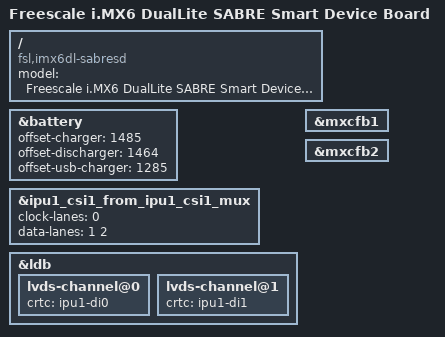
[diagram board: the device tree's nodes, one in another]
// SPDX-License-Identifier: GPL-2.0
//
// Copyright (C) 2013 Freescale Semiconductor, Inc.

/dts-v1/;

#include "imx6dl.dtsi"
#include "imx6qdl-sabresd.dtsi"

/ {
	model = "Freescale i.MX6 DualLite SABRE Smart Device Board";
	compatible = "fsl,imx6dl-sabresd", "fsl,imx6dl";
};

&battery {
	offset-charger = <1485>;
	offset-discharger = <1464>;
	offset-usb-charger = <1285>;
};

&ipu1_csi1_from_ipu1_csi1_mux {
	clock-lanes = <0>;
	data-lanes = <1 2>;
};

&ldb {
	lvds-channel@0 {
		crtc = "ipu1-di0";
	};

	lvds-channel@1 {
		crtc = "ipu1-di1";
	};
};

&mxcfb1 {
	status = "okay";
};

&mxcfb2 {
	status = "okay";
};
